# EFR32MG24A020F1536GM40 register map
Vendor: Silicon Labs; Series: EFR32; File version: B
Registers are 32-bit, read-write, reset 0x0 unless marked. A register's access mark holds for its fields unless they carry their own. Offsets are from the block's base; [hi:lo] are bit positions; 'fields as' and 'values as' point back to an identical list.

## EUSART0_NS — EUSART0_NS Registers
Base 0x5B010000
Same registers: EUSART0_S 0x4B010000
0x00 IPVERSION ro reset 0x2
  [31:0] IPVERSION — IP version ID
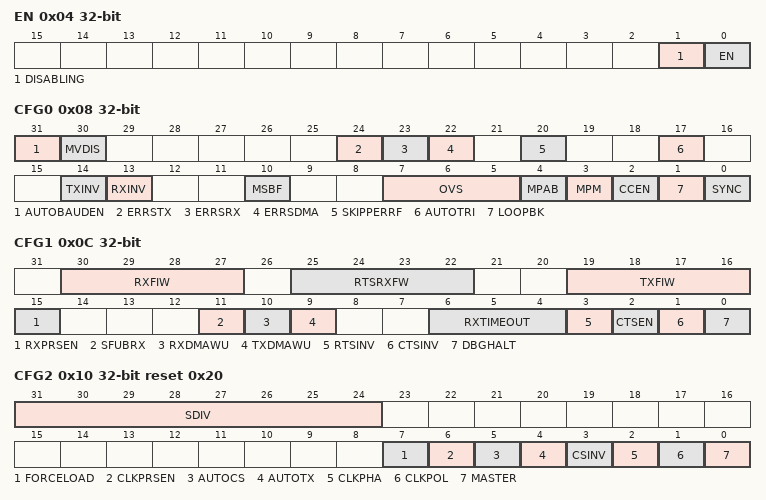
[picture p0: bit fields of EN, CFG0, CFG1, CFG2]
0x04 EN
  [1] DISABLING ro — Disablement busy status
  [0] EN — Module enable
0x08 CFG0
  [31] AUTOBAUDEN — AUTOBAUD detection enable
  [30] MVDIS — Majority Vote Disable
  [24] ERRSTX — Disable TX On Error
    0=DISABLE (Received framing and parity errors have no effect on transmitter); 1=ENABLE (Received framing and parity errors disable the transmitter)
  [23] ERRSRX — Disable RX On Error
    0=DISABLE (Framing and parity errors have no effect on receiver); 1=ENABLE (Framing and parity errors disable the receiver)
  [22] ERRSDMA — Halt DMA Read On Error
    0=DISABLE (Framing and parity errors have no effect on DMA requests from the EUSART); 1=ENABLE (DMA requests from the EUSART are blocked while the PERR or FERR interrupt flags are set)
  [20] SKIPPERRF — Skip Parity Error Frames
  [17] AUTOTRI — Automatic TX Tristate
    0=DISABLE (The output on UARTn_TX when the transmitter is idle is defined by TXINV); 1=ENABLE (UARTn_TX is tristated whenever the transmitter is idle)
  [14] TXINV — Transmitter output Invert
    0=DISABLE (Output from the transmitter is passed unchanged to UARTn_TX); 1=ENABLE (Output from the transmitter is inverted before it is passed to UARTn_TX)
  [13] RXINV — Receiver Input Invert
    0=DISABLE (Input is passed directly to the receiver); 1=ENABLE (Input is inverted before it is passed to the receiver)
  [10] MSBF — Most Significant Bit First
    0=DISABLE (Data is sent with the least significant bit first); 1=ENABLE (Data is sent with the most significant bit first)
  [7:5] OVS — Oversampling
    0=X16 (16X oversampling); 1=X8 (8X oversampling); 2=X6 (6X oversampling); 3=X4 (4X oversampling); 4=DISABLE (Disable oversampling (for LF operation))
  [4] MPAB — Multi-Processor Address-Bit
  [3] MPM — Multi-Processor Mode
    0=DISABLE (The 9th bit of incoming frames has no special function); 1=ENABLE (An incoming frame with the 9th bit equal to MPAB will be loaded into the RX FIFO regardless of RXBLOCK and will result in the MPAB interrupt flag being set)
  [2] CCEN — Collision Check Enable
    0=DISABLE (Collision check is disabled); 1=ENABLE (Collision check is enabled. The receiver must be enabled for the check to be performed)
  [1] LOOPBK — Loopback Enable
    0=DISABLE (The receiver is connected to and receives data from UARTn_RX); 1=ENABLE (The receiver is connected to and receives data from UARTn_TX)
  [0] SYNC — Synchronous Mode
    0=ASYNC (The EUSART operates in asynchronous mode); 1=SYNC (The EUSART operates in synchronous mode)
0x0C CFG1
  [30:27] RXFIW — RX FIFO Interrupt Watermark
    0=ONEFRAME (RXFL status flag and IF are set when the RX FIFO has at least one frame in it.); 1=TWOFRAMES (RXFL status flag and IF are set when the RX FIFO has at least two frames in it.); 2=THREEFRAMES (RXFL status flag and IF are set when the RX FIFO has at least three frames in it.); 3=FOURFRAMES (RXFL status flag and IF are set when the RX FIFO has at least four frames in it.); 4=FIVEFRAMES (RXFL status flag and IF are set when the RX FIFO has at least five frames in it.); 5=SIXFRAMES (RXFL status flag and IF are set when the RX FIFO has at least six frames in it.); 6=SEVENFRAMES (RXFL status flag and IF are set when the RX FIFO has at least seven frames in it.); 7=EIGHTFRAMES (RXFL status flag and IF are set when the RX FIFO has at least eight frames in it.); 8=NINEFRAMES (RXFL status flag and IF are set when the RX FIFO has at least nine frames in it.); 9=TENFRAMES (RXFL status flag and IF are set when the RX FIFO has at least ten frames in it.); 10=ELEVENFRAMES (RXFL status flag and IF are set when the RX FIFO has at least eleven frames in it.); 11=TWELVEFRAMES (RXFL status flag and IF are set when the RX FIFO has at least twelve frames in it.); 12=THIRTEENFRAMES (RXFL status flag and IF are set when the RX FIFO has at least thriteen frames in it.); 13=FOURTEENFRAMES (RXFL status flag and IF are set when the RX FIFO has at least fourteen frames in it.); 14=FIFTEENFRAMES (RXFL status flag and IF are set when the RX FIFO has at least fifteen frames in it.); 15=SIXTEENFRAMES (RXFL status flag and IF are set when the RX FIFO has at least sixteen frames in it.)
  [25:22] RTSRXFW — Request-to-send RX FIFO Watermark
    0=ONEFRAME (RTS is set if there is space for at least one more frame in the RX FIFO.); 1=TWOFRAMES (RTS is set if there is space for at least two more frames in the RX FIFO.); 2=THREEFRAMES (RTS is set if there is space for at least three more frames in the RX FIFO.); 3=FOURFRAMES (RTS is set if there is space for four more frames in the RX FIFO.); 4=FIVEFRAMES (RTS is set if there is space for five more frames in the RX FIFO.); 5=SIXFRAMES (RTS is set if there is space for six more frames in the RX FIFO.); 6=SEVENFRAMES (RTS is set if there is space for seven more frames in the RX FIFO.); 7=EIGHTFRAMES (RTS is set if there is space for eight more frames in the RX FIFO.); 8=NINEFRAMES (RTS is set if there is space for nine more frames in the RX FIFO.); 9=TENFRAMES (RTS is set if there is space for ten more frames in the RX FIFO.); 10=ELEVENFRAMES (RTS is set if there is space for eleven more frames in the RX FIFO.); 11=TWELVEFRAMES (RTS is set if there is space for twelve more frames in the RX FIFO.); 12=THIRTEENFRAMES (RTS is set if there is space for thirteen more frames in the RX FIFO.); 13=FOURTEENFRAMES (RTS is set if there is space for fourteen more frames in the RX FIFO.); 14=FIFTEENFRAMES (RTS is set if there is space for fifteen more frames in the RX FIFO.); 15=SIXTEENFRAMES (RTS is set if there is space for sixteen more frames in the RX FIFO.)
  [19:16] TXFIW — TX FIFO Interrupt Watermark
    0=ONEFRAME (TXFL status flag and IF are set when the TX FIFO has space for at least one more frame.); 1=TWOFRAMES (TXFL status flag and IF are set when the TX FIFO has space for at least two more frames.); 2=THREEFRAMES (TXFL status flag and IF are set when the TX FIFO has space for at least three more frames.); 3=FOURFRAMES (TXFL status flag and IF are set when the TX FIFO has space for at least four more frames.); 4=FIVEFRAMES (TXFL status flag and IF are set when the TX FIFO has space for at least five more frames.); 5=SIXFRAMES (TXFL status flag and IF are set when the TX FIFO has space for at least six more frames.); 6=SEVENFRAMES (TXFL status flag and IF are set when the TX FIFO has space for at least seven more frames.); 7=EIGHTFRAMES (TXFL status flag and IF are set when the TX FIFO has space for at least eight more frames.); 8=NINEFRAMES (TXFL status flag and IF are set when the TX FIFO has space for at least nine more frames.); 9=TENFRAMES (TXFL status flag and IF are set when the TX FIFO has space for at least ten more frames.); 10=ELEVENFRAMES (TXFL status flag and IF are set when the TX FIFO has space for at least eleven more frames.); 11=TWELVEFRAMES (TXFL status flag and IF are set when the TX FIFO has space for at least twelve more frames.); 12=THIRTEENFRAMES (TXFL status flag and IF are set when the TX FIFO has space for at least thriteen more frames.); 13=FOURTEENFRAMES (TXFL status flag and IF are set when the TX FIFO has space for at least fourteen more frames.); 14=FIFTEENFRAMES (TXFL status flag and IF are set when the TX FIFO has space for at least fifteen more frames.); 15=SIXTEENFRAMES (TXFL status flag and IF are set when the TX FIFO has space for at least sixteen more frames.)
  [15] RXPRSEN — PRS RX Enable
  [11] SFUBRX — Start Frame Unblock Receiver
  [10] RXDMAWU — Receiver DMA Wakeup
  [9] TXDMAWU — Transmitter DMA Wakeup
  [6:4] RXTIMEOUT
    0=DISABLED; 1=ONEFRAME; 2=TWOFRAMES; 3=THREEFRAMES; 4=FOURFRAMES; 5=FIVEFRAMES; 6=SIXFRAMES; 7=SEVENFRAMES
  [3] RTSINV — Request-to-send Invert Enable
    0=DISABLE (The RTS pin is active low); 1=ENABLE (The RTS pin is active high)
  [2] CTSEN — Clear-to-send Enable
    0=DISABLE (Ignore CTS); 1=ENABLE (Stop transmitting when CTS is inactive)
  [1] CTSINV — Clear-to-send Invert Enable
    0=DISABLE (The CTS pin is active low); 1=ENABLE (The CTS pin is active high)
  [0] DBGHALT — Debug halt
    0=DISABLE (Continue normal EUSART operation even if core is halted); 1=ENABLE (If core is halted, receive one frame and then halt reception by deactivating RTS. Next frame reception happens when the core is unhalted during single stepping.)
0x10 CFG2 reset 0x20
  [31:24] SDIV — Sync Clock Div
  [7] FORCELOAD — Force Load to Shift Register
  [6] CLKPRSEN — PRS CLK Enable
  [5] AUTOCS — Automatic Chip Select
  [4] AUTOTX — Always Transmit When RXFIFO Not Full
  [3] CSINV — Chip Select Invert
    0=AL (Chip select is active low); 1=AH (Chip select is active high)
  [2] CLKPHA — Clock Edge for Setup/Sample
    0=SAMPLELEADING (Data is sampled on the leading edge and set-up on the trailing edge of the bus clock in synchronous mode); 1=SAMPLETRAILING (Data is set-up on the leading edge and sampled on the trailing edge of the bus clock in synchronous mode)
  [1] CLKPOL — Clock Polarity
    0=IDLELOW (The bus clock used in synchronous mode has a low base value); 1=IDLEHIGH (The bus clock used in synchronous mode has a high base value)
  [0] MASTER — Main mode
    0=SLAVE (Secondary mode); 1=MASTER (Main mode)
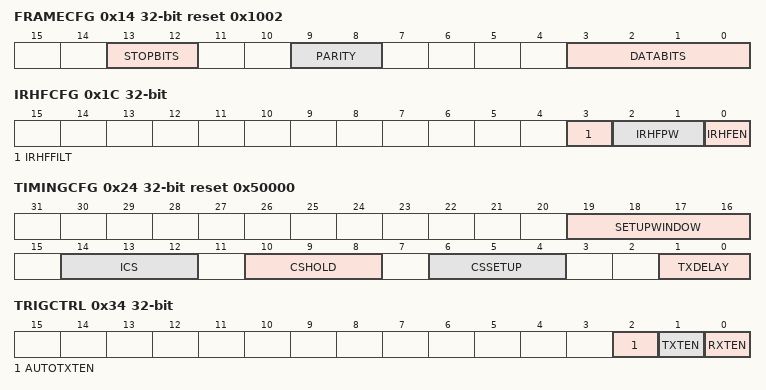
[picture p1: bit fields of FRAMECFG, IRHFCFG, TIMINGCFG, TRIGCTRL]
0x14 FRAMECFG reset 0x1002
  [13:12] STOPBITS — Stop-Bit Mode
    0=HALF (The transmitter generates a half stop bit. Stop-bits are not verified by receiver); 1=ONE (One stop bit is generated and verified); 2=ONEANDAHALF (The transmitter generates one and a half stop bit. The receiver verifies the first stop bit); 3=TWO (The transmitter generates two stop bits. The receiver checks the first stop-bit only)
  [9:8] PARITY — Parity-Bit Mode
    0=NONE (Parity bits are not used); 2=EVEN (Even parity are used. Parity bits are automatically generated and checked by hardware.); 3=ODD (Odd parity is used. Parity bits are automatically generated and checked by hardware.)
  [3:0] DATABITS — Data-Bit Mode
    1=SEVEN (Each frame contains 7 data bits); 2=EIGHT (Each frame contains 8 data bits); 3=NINE (Each frame contains 9 data bits); 4=TEN (Each frame contains 10 data bits); 5=ELEVEN (Each frame contains 11 data bits); 6=TWELVE (Each frame contains 12 data bits); 7=THIRTEEN (Each frame contains 13 data bits); 8=FOURTEEN (Each frame contains 14 data bits); 9=FIFTEEN (Each frame contains 15 data bits); 10=SIXTEEN (Each frame contains 16 data bits)
0x18 DTXDATCFG
  [15:0] DTXDAT — Default TX DATA
0x1C IRHFCFG
  [3] IRHFFILT — IrDA RX Filter
    0=DISABLE (No filter enabled); 1=ENABLE (Filter enabled. IrDA pulse must be high for at least 5 consecutive clock cycles to be detected)
  [2:1] IRHFPW — IrDA TX Pulse Width
    0=ONE (IrDA pulse width is 1/16 for OVS=0 and 1/8 for OVS=1); 1=TWO (IrDA pulse width is 2/16 for OVS=0 and 2/8 for OVS=1); 2=THREE (IrDA pulse width is 3/16 for OVS=0 and 3/8 for OVS=1); 3=FOUR (IrDA pulse width is 4/16 for OVS=0 and 4/8 for OVS=1)
  [0] IRHFEN — Enable IrDA Module
0x20 IRLFCFG
  [0] IRLFEN — Pulse Generator/Extender Enable
0x24 TIMINGCFG reset 0x50000
  [19:16] SETUPWINDOW
  [14:12] ICS — Inter-Character Spacing
    0=ZERO (There is no space between charcters); 1=ONE (Create a space of 1 baud-times between frames); 2=TWO (Create a space of 2 baud-times between frames); 3=THREE (Create a space of 3 baud-times between frames); 4=FOUR (Create a space of 4 baud-times between frames); 5=FIVE (Create a space of 5 baud-times between frames); 6=SIX (Create a space of 6 baud-times between frames); 7=SEVEN (Create a space of 7 baud-times between frames)
  [10:8] CSHOLD — Chip Select Hold
    0=ZERO (CS is de-asserted half or 1 baud-time after the end of transmission depending on CLKPHASE equal to 1 or 0 respectively); 1=ONE (CS is de-asserted 1 additional baud-time after the end of transmission); 2=TWO (CS is de-asserted 2 additional baud-times after the end of transmission); 3=THREE (CS is de-asserted 3 additional baud-times after the end of transmission); 4=FOUR (CS is de-asserted 4 additional baud-times after the end of transmission); 5=FIVE (CS is de-asserted 5 additional baud-times after the end of transmission); 6=SIX (CS is de-asserted 6 additional baud-times after the end of transmission); 7=SEVEN (CS is de-asserted 7 additional baud-times after the end of transmission)
  [6:4] CSSETUP — Chip Select Setup
    0=ZERO (CS is asserted half or 1 baud-time before the start of transmission depending on CLKPHASE equal to 1 or 0 respectively); 1=ONE (CS is asserted 1 additional baud-time before start of transmission); 2=TWO (CS is asserted 2 additional baud-times before start of transmission); 3=THREE (CS is asserted 3 additional baud-times before start of transmission); 4=FOUR (CS is asserted 4 additional baud-times before start of transmission); 5=FIVE (CS is asserted 5 additional baud-times before start of transmission); 6=SIX (CS is asserted 6 additional baud-times before start of transmission); 7=SEVEN (CS is asserted 7 additional baud-times before start of transmission)
  [1:0] TXDELAY — TX Delay Transmission
    0=NONE (Frames are transmitted immediately.); 1=SINGLE (Transmission of new frames is delayed by a single bit period.); 2=DOUBLE (Transmission of new frames is delayed by a two bit periods.); 3=TRIPPLE (Transmission of new frames is delayed by a three bit periods.)
0x28 STARTFRAMECFG
  [8:0] STARTFRAME
0x2C SIGFRAMECFG
  [31:0] SIGFRAME — Signal Frame Value
0x30 CLKDIV
  [22:3] DIV — Fractional Clock Divider
0x34 TRIGCTRL
  [2] AUTOTXTEN — AUTOTX Trigger Enable
  [1] TXTEN — Transmit Trigger Enable
  [0] RXTEN — Receive Trigger Enable
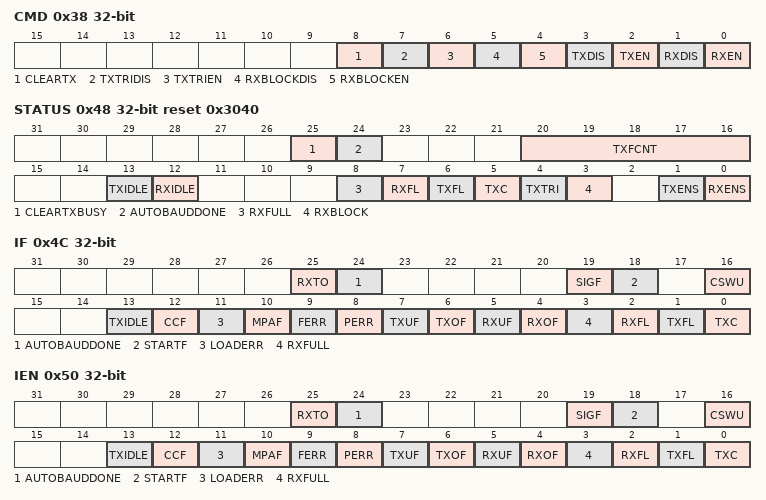
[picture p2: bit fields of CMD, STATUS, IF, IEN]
0x38 CMD wo
  [8] CLEARTX — Clear TX FIFO
  [7] TXTRIDIS — Transmitter Tristate Disable
  [6] TXTRIEN — Transmitter Tristate Enable
  [5] RXBLOCKDIS — Receiver Block Disable
  [4] RXBLOCKEN — Receiver Block Enable
  [3] TXDIS — Transmitter Disable
  [2] TXEN — Transmitter Enable
  [1] RXDIS — Receiver Disable
  [0] RXEN — Receiver Enable
0x3C RXDATA ro
  [15:0] RXDATA — RX Data and Control bits
0x40 RXDATAP ro
  [15:0] RXDATAP — RX Data Peek
0x44 TXDATA wo
  [15:0] TXDATA — TX Data and Control bits
0x48 STATUS ro reset 0x3040
  [25] CLEARTXBUSY — TX FIFO Clear Busy
  [24] AUTOBAUDDONE — Auto Baud Rate Detection Completed
  [20:16] TXFCNT — Valid entries in TX FIFO
  [13] TXIDLE
  [12] RXIDLE
  [8] RXFULL — RX FIFO Full
  [7] RXFL — RX FIFO Level
  [6] TXFL — TX FIFO Level
  [5] TXC — TX Complete
  [4] TXTRI — Transmitter Tristated
  [3] RXBLOCK — Block Incoming Data
  [1] TXENS — Transmitter Enable Status
  [0] RXENS — Receiver Enable Status
0x4C IF
  [25] RXTO — RX Timeout Interrupt Flag
  [24] AUTOBAUDDONE — Auto Baud Complete Interrupt Flag
  [19] SIGF — Signal Frame Interrupt Flag
  [18] STARTF — Start Frame Interrupt Flag
  [16] CSWU — CS Wake-up Interrupt Flag
  [13] TXIDLE — TX Idle Interrupt Flag
  [12] CCF — Collision Check Fail Interrupt Flag
  [11] LOADERR — Load Error Interrupt Flag
  [10] MPAF — Multi-Processor Address Frame Interrupt
  [9] FERR — Framing Error Interrupt Flag
  [8] PERR — Parity Error Interrupt Flag
  [7] TXUF — TX FIFO Underflow Interrupt Flag
  [6] TXOF — TX FIFO Overflow Interrupt Flag
  [5] RXUF — RX FIFO Underflow Interrupt Flag
  [4] RXOF — RX FIFO Overflow Interrupt Flag
  [3] RXFULL — RX FIFO Full Interrupt Flag
  [2] RXFL — RX FIFO Level Interrupt Flag
  [1] TXFL — TX FIFO Level Interrupt Flag
  [0] TXC — TX Complete Interrupt Flag
0x50 IEN
  [25] RXTO — RX Timeout Enable
  [24] AUTOBAUDDONE — Auto Baud Complete Enable
  [19] SIGF — Signal Frame Enable
  [18] STARTF — Start Frame Enable
  [16] CSWU — CS Wake-up Enable
  [13] TXIDLE — TX IDLE Enable
  [12] CCF — Collision Check Fail Enable
  [11] LOADERR — Load Error Enable
  [10] MPAF — Multi-Processor Addr Frame Enable
  [9] FERR — Framing Error Enable
  [8] PERR — Parity Error Enable
  [7] TXUF — TX FIFO Underflow Enable
  [6] TXOF — TX FIFO Overflow Enable
  [5] RXUF — RX FIFO Underflow Enable
  [4] RXOF — RX FIFO Overflow Enable
  [3] RXFULL — RX FIFO Full Enable
  [2] RXFL — RX FIFO Level Enable
  [1] TXFL — TX FIFO Level Enable
  [0] TXC — TX Complete Enable
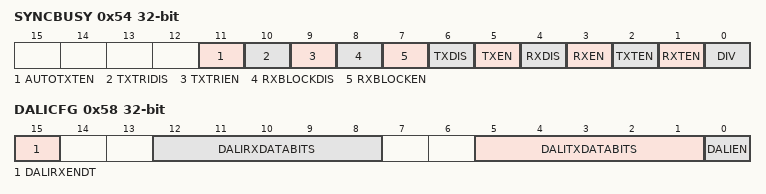
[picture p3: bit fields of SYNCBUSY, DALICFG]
0x54 SYNCBUSY ro
  [11] AUTOTXTEN — SYNCBUSY for AUTOTXTEN in TRIGCTRL
  [10] TXTRIDIS — SYNCBUSY in TXTRIDIS in CMD
  [9] TXTRIEN — SYNCBUSY for TXTRIEN in CMD
  [8] RXBLOCKDIS — SYNCBUSY for RXBLOCKDIS in CMD
  [7] RXBLOCKEN — SYNCBUSY for RXBLOCKEN in CMD
  [6] TXDIS — SYNCBUSY for TXDIS in CMD
  [5] TXEN — SYNCBUSY for TXEN in CMD
  [4] RXDIS — SYNCBUSY for RXDIS in CMD
  [3] RXEN — SYNCBUSY for RXEN in CMD
  [2] TXTEN — SYNCBUSY for TXTEN in TRIGCTRL
  [1] RXTEN — SYNCBUSY for RXTEN in TRIGCTRL
  [0] DIV — SYNCBUSY for DIV in CLKDIV
0x58 DALICFG
  [15] DALIRXENDT — DALI RX Enabled During Transmission
  [12:8] DALIRXDATABITS
    0=EIGHT (Each frame contains 8 data bits); 1=NINE (Each frame contains 9 data bits); 2=TEN (Each frame contains 10 data bits); 3=ELEVEN (Each frame contains 11 data bits); 4=TWELVE (Each frame contains 12 data bits); 5=THIRTEEN (Each frame contains 13 data bits); 6=FOURTEEN (Each frame contains 14 data bits); 7=FIFTEEN (Each frame contains 15 data bits); 8=SIXTEEN (Each frame contains 16 data bits); 9=SEVENTEEN (Each frame contains 17 data bits); 10=EIGHTEEN (Each frame contains 18 data bits); 11=NINETEEN (Each frame contains 19 data bits); 12=TWENTY (Each frame contains 20 data bits); 13=TWENTYONE (Each frame contains 21 data bits); 14=TWENTYTWO (Each frame contains 22 data bits); 15=TWENTYTHREE (Each frame contains 23 data bits); 16=TWENTYFOUR (Each frame contains 24 data bits); 17=TWENTYFIVE (Each frame contains 25 data bits); 18=TWENTYSIX (Each frame contains 26 data bits); 19=TWENTYSEVEN (Each frame contains 27 data bits); 20=TWENTYEIGHT (Each frame contains 28 data bits); 21=TWENTYNINE (Each frame contains 29 data bits); 22=THIRTY (Each frame contains 30 data bits); 23=THIRTYONE (Each frame contains 31 data bits); 24=THIRTYTWO (Each frame contains 32 data bits)
  [5:1] DALITXDATABITS
    values as DALIRXDATABITS
  [0] DALIEN — DALI Enable Bit

## EUSART1_NS — EUSART1_NS Registers
Base 0x500A0000
Same registers: EUSART1_S 0x400A0000
Registers as EUSART0_NS, without IRLFCFG; these are added or differ:
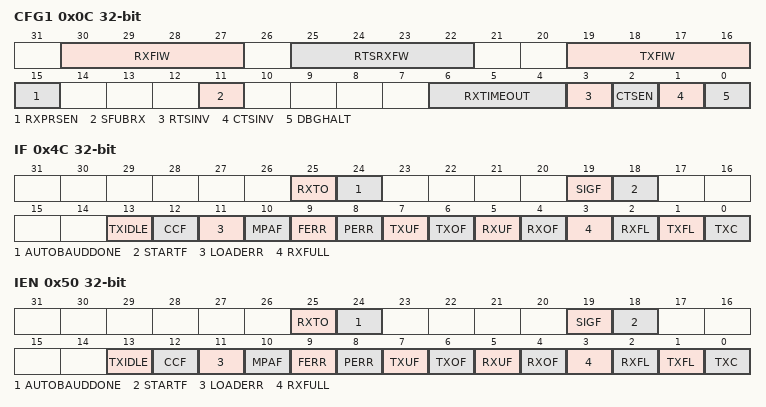
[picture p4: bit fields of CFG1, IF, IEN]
0x0C CFG1
  [30:27] RXFIW — RX FIFO Interrupt Watermark
    values as EUSART0_NS.CFG1.RXFIW
  [25:22] RTSRXFW — Request-to-send RX FIFO Watermark
    values as EUSART0_NS.CFG1.RTSRXFW
  [19:16] TXFIW — TX FIFO Interrupt Watermark
    values as EUSART0_NS.CFG1.TXFIW
  [15] RXPRSEN — PRS RX Enable
  [11] SFUBRX — Start Frame Unblock Receiver
  [6:4] RXTIMEOUT
    0=DISABLED; 1=ONEFRAME; 2=TWOFRAMES; 3=THREEFRAMES; 4=FOURFRAMES; 5=FIVEFRAMES; 6=SIXFRAMES; 7=SEVENFRAMES
  [3] RTSINV — Request-to-send Invert Enable
    0=DISABLE (The RTS pin is active low); 1=ENABLE (The RTS pin is active high)
  [2] CTSEN — Clear-to-send Enable
    0=DISABLE (Ignore CTS); 1=ENABLE (Stop transmitting when CTS is inactive)
  [1] CTSINV — Clear-to-send Invert Enable
    0=DISABLE (The CTS pin is active low); 1=ENABLE (The CTS pin is active high)
  [0] DBGHALT — Debug halt
    values as EUSART0_NS.CFG1.DBGHALT
0x4C IF
  [25] RXTO — RX Timeout Interrupt Flag
  [24] AUTOBAUDDONE — Auto Baud Complete Interrupt Flag
  [19] SIGF — Signal Frame Interrupt Flag
  [18] STARTF — Start Frame Interrupt Flag
  [13] TXIDLE — TX Idle Interrupt Flag
  [12] CCF — Collision Check Fail Interrupt Flag
  [11] LOADERR — Load Error Interrupt Flag
  [10] MPAF — Multi-Processor Address Frame Interrupt
  [9] FERR — Framing Error Interrupt Flag
  [8] PERR — Parity Error Interrupt Flag
  [7] TXUF — TX FIFO Underflow Interrupt Flag
  [6] TXOF — TX FIFO Overflow Interrupt Flag
  [5] RXUF — RX FIFO Underflow Interrupt Flag
  [4] RXOF — RX FIFO Overflow Interrupt Flag
  [3] RXFULL — RX FIFO Full Interrupt Flag
  [2] RXFL — RX FIFO Level Interrupt Flag
  [1] TXFL — TX FIFO Level Interrupt Flag
  [0] TXC — TX Complete Interrupt Flag
0x50 IEN
  [25] RXTO — RX Timeout Enable
  [24] AUTOBAUDDONE — Auto Baud Complete Enable
  [19] SIGF — Signal Frame Enable
  [18] STARTF — Start Frame Enable
  [13] TXIDLE — TX IDLE Enable
  [12] CCF — Collision Check Fail Enable
  [11] LOADERR — Load Error Enable
  [10] MPAF — Multi-Processor Addr Frame Enable
  [9] FERR — Framing Error Enable
  [8] PERR — Parity Error Enable
  [7] TXUF — TX FIFO Underflow Enable
  [6] TXOF — TX FIFO Overflow Enable
  [5] RXUF — RX FIFO Underflow Enable
  [4] RXOF — RX FIFO Overflow Enable
  [3] RXFULL — RX FIFO Full Enable
  [2] RXFL — RX FIFO Level Enable
  [1] TXFL — TX FIFO Level Enable
  [0] TXC — TX Complete Enable
